# MC3_LSE_ICONT register map
Vendor: Texas Instruments
Peripheral module from a debugger description file (folder DRA75x_DRA74x).
Registers are 32-bit, access not given, reset 0x1 unless marked. A register's access mark holds for its fields unless they carry their own. Offsets are as the file gives them; lines under a group give offsets from that group; [hi:lo] are bit positions; {n}, {i} and the like mark numbered series; 'fields as' and 'values as' point back to an identical list; <NAME> marks a mode.

## MC3_LSE_ICONT
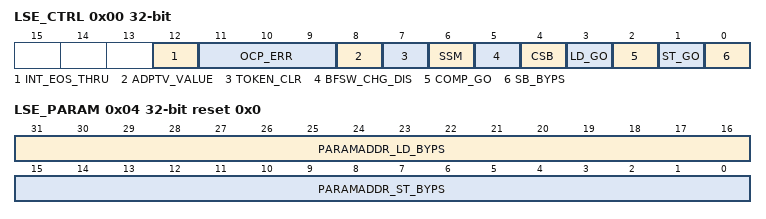
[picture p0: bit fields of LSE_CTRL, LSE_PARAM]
0x00 LSE_CTRL — Controller
  [12] INT_EOS_THRU rw — int_eos through
    0=LSE_0 (LSE does the process for slice boundary after receiving int_eos.); 1=SYNCBOX_MC3_1 (int_eos is passed through to SYNCBOX_MC3 without the process for slice boundary.)
  [11:9] OCP_ERR — OCP error status bit [11]: OCP DMA IP_CORE side [10]: OCP DMA SL2 side [9]: OCP CFG IP_CORE side.Writing 0 is ignored. These bits remain 1 until RESET or until host sets to 1. . (access RW WSpecial)
    0=When_Sresp_is_not_ERR; 1=When_Sresp_is_ERR
  [8] ADPTV_VALUE ro — Status Adaptv_add() value This signal is cleared, if Token_clr = 1.
  [7] TOKEN_CLR — LSE internal signals are initialized to understand prologue(first MB) as below: -token status signal -token start/end signal -DMA pointer. Writing 0 is ignored. Writing 1 clears some internal signal. This is a self-clearing bit. The host always reads 0. If this is not used for initialization at prologue, some internal signal is kept. Also, synchronization does not function well. (access W WSpecial)
  [6] SSM rw — Single step mode
    0=Normal_mode; 1=Enable_single_step_mode
  [5] BFSW_CHG_DIS rw — Disabled internal BFSW change
    0=BFSW_LSE_BFSW_LD_0 (Enable internal BFSW change (default). Then, LSE controls BFSW after LD task finished.); 1=BFSW_BFSW_LD_GO,_ST_GO)_1 (Disable BFSW change (if host wants to control BFSW with each task step by step with LD_GO, Comp_GO and ST_GO))
  [4] CSB — Command status (access RW WSpecial)
    0=LSE_command_is_defined; 1=LSE_RESET_1 (LSE command is undefined. Writing 0 is ignored. These bits remain 1 until RESET or Token_clr or until host sets to 1.)
  [3] LD_GO — Execute LOAD task on bypass mode Target ParamAddr_ld_byps need to set before this bit is set. (access RW WSpecial)
    0=LD_0 (Idle. Writing 0 is ignored This bit is cleared after LD task finishes..); 1=LD_LSE_LOAD_1 (Execute LD task. LSE access to ParamAddr_ld_byps and execute the command for LOAD task.)
  [2] COMP_GO — Execute Comp task on bypass modeIn normal mode, LSE executes COMP commands, followed by LD commands. . (access RW WSpecial)
    0=Idle. Writing 0 is ignored This bit is cleared after Comp task finishes.; 1=LSE_1 (Execute Comp task. In single step mode, LSE access to ParamAddr_ld_byps and execute the command for Comp task.)
  [1] ST_GO — Execute Store task on bypass mode Target ParamAddr_st_byps needs to set before this bit is set. (access RW WSpecial)
    0=ST_0 (Idle. Writing 0 is ignored This bit is cleared after ST task finishes.); 1=LSE_1 (Execute Store task. LSE access to ParamAddr_st_byps and execute the command for Store task.)
  [0] SB_BYPS rw — SYNCBOX_MC3 bypass mode
    0=LSE_SYNCBOX_MC3_0 (LSE function normal SYNCBOX_MC3 mode and waits NewTaskSignal. This value should not change during execution.); 1=LSE_SYNCBOX_MC3_1 (LSE functions SYNCBOX_MC3 bypass mode and executes the task of go_bit.)
0x04 LSE_PARAM rw reset 0x0 — Parameter address for SB Bypass mode
  [31:16] PARAMADDR_LD_BYPS — Only used in bypass mode. Address of the first command of LD and COMP sequence [128-bit word unit]. This is 128-bit word address, not byte address. The conversion from byte address to 128-bit word address should be done by the CPU. IfLSE_CTRL SB_BYPS is 1, this value is used. In bypass mode, this address is given through this field, instead of through SYNCBOX_MC3. Also, this field is used in single-step mode.
  [15:0] PARAMADDR_ST_BYPS — Only used in bypass mode. Address of the first command of ST sequence [128-bit word unit]. This is 128-bit word address, not byte address. The conversion from byte address to 128-bit word address should be done by the CPU. IfLSE_CTRL SB_BYPS is 1, this value is used. In bypass mode, this address is given through this field, instead of through SYNCBOX_MC3. .Also, this field is used in single-step mode.
